VERSION ""

NS_ :

BS_:

BU_: ECU_A

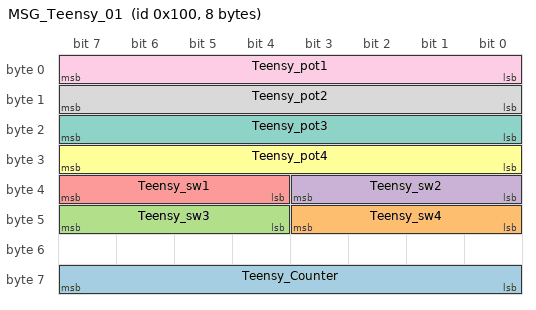
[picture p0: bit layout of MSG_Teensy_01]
BO_ 256 MSG_Teensy_01: 8 ECU_A
 SG_ Teensy_Counter : 56|8@1+ (1,0) [0|0] "" Vector__XXX
 SG_ Teensy_sw4 : 40|4@1- (1,0) [0|0] "" Vector__XXX
 SG_ Teensy_sw3 : 44|4@1- (1,0) [0|0] "" Vector__XXX
 SG_ Teensy_sw2 : 32|4@1- (1,0) [0|0] "" Vector__XXX
 SG_ Teensy_sw1 : 36|4@1- (1,0) [0|0] "" Vector__XXX
 SG_ Teensy_pot4 : 24|8@1+ (1,0) [0|0] "" Vector__XXX
 SG_ Teensy_pot3 : 16|8@1+ (1,0) [0|0] "" Vector__XXX
 SG_ Teensy_pot2 : 8|8@1+ (1,0) [0|0] "" Vector__XXX
 SG_ Teensy_pot1 : 0|8@1+ (1,0) [0|0] "" Vector__XXX

BA_DEF_  "BusType" STRING ;
BA_DEF_DEF_  "BusType" "CAN";
